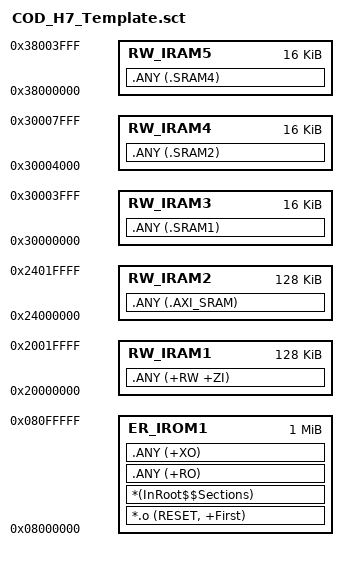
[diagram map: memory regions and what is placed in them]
; *************************************************************
; *** Scatter-Loading Description File generated by uVision ***
; *************************************************************

LR_IROM1 0x08000000 0x00100000  {    ; load region size_region
  ER_IROM1 0x08000000 0x00100000  {  ; load address = execution address
   *.o (RESET, +First)
   *(InRoot$$Sections)
   .ANY (+RO)
   .ANY (+XO)
  }
 
  RW_IRAM1 0x20000000 0x00020000  {  ; RW data
   .ANY (+RW +ZI)
  }
 
 RW_IRAM2 0x24000000 0x00020000  {
   .ANY (.AXI_SRAM)
  }

 RW_IRAM3 0x30000000 0x00004000  {
   .ANY (.SRAM1)
  }

 RW_IRAM4 0x30004000 0x00004000  {
   .ANY (.SRAM2)
  }

 RW_IRAM5 0x38000000 0x00004000  {
   .ANY (.SRAM4)
  }

}

